# ESP32-P4 register map
Vendor: ESPRESSIF SYSTEMS (SHANGHAI) CO., LTD.; Series: ESP32 P-Series; File version: 3
CPU: RV32IMAFC r0p0, little endian, no MPU, FPU, 0 interrupt priority bits
Address unit: 32 bits
Registers are 32-bit, read-write, reset 0x0 unless marked. A register's access mark holds for its fields unless they carry their own. Offsets are from the block's base; [hi:lo] are bit positions; {n}, {i} and the like mark numbered series.

## CACHE (part 2 of 3) — CACHE Peripheral
Base 0x3FF10000
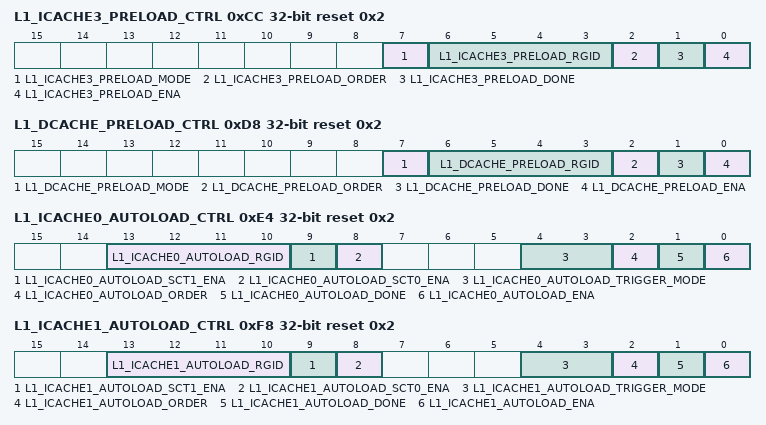
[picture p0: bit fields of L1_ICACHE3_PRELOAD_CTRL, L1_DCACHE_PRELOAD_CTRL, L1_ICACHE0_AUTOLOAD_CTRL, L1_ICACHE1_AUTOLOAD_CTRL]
0xCC L1_ICACHE3_PRELOAD_CTRL ro reset 0x2 — L1 instruction Cache 3 preload-operation control register
  [7] L1_ICACHE3_PRELOAD_MODE — The bit is used to configure the mode of l1 icache3 preload, 0: load data from next level memory, 1: not load data from next level memory.
  [6:3] L1_ICACHE3_PRELOAD_RGID — The bit is used to set the gid of l1 icache3 preload.
  [2] L1_ICACHE3_PRELOAD_ORDER — The bit is used to configure the direction of preload operation. 0: ascending, 1: descending.
  [1] L1_ICACHE3_PRELOAD_DONE — The bit is used to indicate whether preload operation is finished or not. 0: not finished. 1: finished.
  [0] L1_ICACHE3_PRELOAD_ENA — The bit is used to enable preload operation on L1-ICache3. It will be cleared by hardware automatically after preload operation is done.
0xD0 L1_ICACHE3_PRELOAD_ADDR ro — L1 instruction Cache 3 preload address configure register
  [31:0] L1_ICACHE3_PRELOAD_ADDR — Those bits are used to configure the start virtual address of preload on L1-ICache3, which should be used together with L1_ICACHE3_PRELOAD_SIZE_REG
0xD4 L1_ICACHE3_PRELOAD_SIZE ro — L1 instruction Cache 3 preload size configure register
  [13:0] L1_ICACHE3_PRELOAD_SIZE — Those bits are used to configure the size of the first section of prelock on L1-ICache3, which should be used together with L1_ICACHE3_PRELOAD_ADDR_REG
0xD8 L1_DCACHE_PRELOAD_CTRL access per field reset 0x2 — L1 data Cache preload-operation control register
  [7] L1_DCACHE_PRELOAD_MODE rw — The bit is used to configure the mode of l1 dcache preload, 0: load data from next level memory, 1: not load data from next level memory.
  [6:3] L1_DCACHE_PRELOAD_RGID rw — The bit is used to set the gid of l1 dcache preload.
  [2] L1_DCACHE_PRELOAD_ORDER rw — The bit is used to configure the direction of preload operation. 0: ascending, 1: descending.
  [1] L1_DCACHE_PRELOAD_DONE ro — The bit is used to indicate whether preload operation is finished or not. 0: not finished. 1: finished.
  [0] L1_DCACHE_PRELOAD_ENA rw — The bit is used to enable preload operation on L1-DCache. It will be cleared by hardware automatically after preload operation is done.
0xDC L1_DCACHE_PRELOAD_ADDR — L1 data Cache preload address configure register
  [31:0] L1_DCACHE_PRELOAD_ADDR — Those bits are used to configure the start virtual address of preload on L1-DCache, which should be used together with L1_DCACHE_PRELOAD_SIZE_REG
0xE0 L1_DCACHE_PRELOAD_SIZE — L1 data Cache preload size configure register
  [13:0] L1_DCACHE_PRELOAD_SIZE — Those bits are used to configure the size of the first section of prelock on L1-DCache, which should be used together with L1_DCACHE_PRELOAD_ADDR_REG
0xE4 L1_ICACHE0_AUTOLOAD_CTRL access per field reset 0x2 — L1 instruction Cache 0 autoload-operation control register
  [13:10] L1_ICACHE0_AUTOLOAD_RGID rw — The bit is used to set the gid of l1 icache0 autoload.
  [9] L1_ICACHE0_AUTOLOAD_SCT1_ENA rw — The bit is used to enable the second section for autoload operation on L1-ICache0.
  [8] L1_ICACHE0_AUTOLOAD_SCT0_ENA rw — The bit is used to enable the first section for autoload operation on L1-ICache0.
  [4:3] L1_ICACHE0_AUTOLOAD_TRIGGER_MODE rw — The field is used to configure trigger mode of autoload operation on L1-ICache0. 0/3: miss-trigger, 1: hit-trigger, 2: miss-hit-trigger.
  [2] L1_ICACHE0_AUTOLOAD_ORDER rw — The bit is used to configure the direction of autoload operation on L1-ICache0. 0: ascending. 1: descending.
  [1] L1_ICACHE0_AUTOLOAD_DONE ro — The bit is used to indicate whether autoload operation on L1-ICache0 is finished or not. 0: not finished. 1: finished.
  [0] L1_ICACHE0_AUTOLOAD_ENA rw — The bit is used to enable and disable autoload operation on L1-ICache0. 1: enable, 0: disable.
0xE8 L1_ICACHE0_AUTOLOAD_SCT0_ADDR — L1 instruction Cache 0 autoload section 0 address configure register
  [31:0] L1_ICACHE0_AUTOLOAD_SCT0_ADDR — Those bits are used to configure the start virtual address of the first section for autoload operation on L1-ICache0. Note that it should be used together with L1_ICACHE0_AUTOLOAD_SCT0_SIZE and L1_ICACHE_AUTOLOAD_SCT0_ENA.
0xEC L1_ICACHE0_AUTOLOAD_SCT0_SIZE — L1 instruction Cache 0 autoload section 0 size configure register
  [27:0] L1_ICACHE0_AUTOLOAD_SCT0_SIZE — Those bits are used to configure the size of the first section for autoload operation on L1-ICache0. Note that it should be used together with L1_ICACHE0_AUTOLOAD_SCT0_ADDR and L1_ICACHE_AUTOLOAD_SCT0_ENA.
0xF0 L1_ICACHE0_AUTOLOAD_SCT1_ADDR — L1 instruction Cache 0 autoload section 1 address configure register
  [31:0] L1_ICACHE0_AUTOLOAD_SCT1_ADDR — Those bits are used to configure the start virtual address of the second section for autoload operation on L1-ICache0. Note that it should be used together with L1_ICACHE0_AUTOLOAD_SCT1_SIZE and L1_ICACHE_AUTOLOAD_SCT1_ENA.
0xF4 L1_ICACHE0_AUTOLOAD_SCT1_SIZE — L1 instruction Cache 0 autoload section 1 size configure register
  [27:0] L1_ICACHE0_AUTOLOAD_SCT1_SIZE — Those bits are used to configure the size of the second section for autoload operation on L1-ICache0. Note that it should be used together with L1_ICACHE0_AUTOLOAD_SCT1_ADDR and L1_ICACHE_AUTOLOAD_SCT1_ENA.
0xF8 L1_ICACHE1_AUTOLOAD_CTRL access per field reset 0x2 — L1 instruction Cache 1 autoload-operation control register
  [13:10] L1_ICACHE1_AUTOLOAD_RGID rw — The bit is used to set the gid of l1 icache1 autoload.
  [9] L1_ICACHE1_AUTOLOAD_SCT1_ENA rw — The bit is used to enable the second section for autoload operation on L1-ICache1.
  [8] L1_ICACHE1_AUTOLOAD_SCT0_ENA rw — The bit is used to enable the first section for autoload operation on L1-ICache1.
  [4:3] L1_ICACHE1_AUTOLOAD_TRIGGER_MODE rw — The field is used to configure trigger mode of autoload operation on L1-ICache1. 0/3: miss-trigger, 1: hit-trigger, 2: miss-hit-trigger.
  [2] L1_ICACHE1_AUTOLOAD_ORDER rw — The bit is used to configure the direction of autoload operation on L1-ICache1. 0: ascending. 1: descending.
  [1] L1_ICACHE1_AUTOLOAD_DONE ro — The bit is used to indicate whether autoload operation on L1-ICache1 is finished or not. 0: not finished. 1: finished.
  [0] L1_ICACHE1_AUTOLOAD_ENA rw — The bit is used to enable and disable autoload operation on L1-ICache1. 1: enable, 0: disable.
0xFC L1_ICACHE1_AUTOLOAD_SCT0_ADDR — L1 instruction Cache 1 autoload section 0 address configure register
  [31:0] L1_ICACHE1_AUTOLOAD_SCT0_ADDR — Those bits are used to configure the start virtual address of the first section for autoload operation on L1-ICache1. Note that it should be used together with L1_ICACHE1_AUTOLOAD_SCT0_SIZE and L1_ICACHE_AUTOLOAD_SCT0_ENA.
0x100 L1_ICACHE1_AUTOLOAD_SCT0_SIZE — L1 instruction Cache 1 autoload section 0 size configure register
  [27:0] L1_ICACHE1_AUTOLOAD_SCT0_SIZE — Those bits are used to configure the size of the first section for autoload operation on L1-ICache1. Note that it should be used together with L1_ICACHE1_AUTOLOAD_SCT0_ADDR and L1_ICACHE_AUTOLOAD_SCT0_ENA.
0x104 L1_ICACHE1_AUTOLOAD_SCT1_ADDR — L1 instruction Cache 1 autoload section 1 address configure register
  [31:0] L1_ICACHE1_AUTOLOAD_SCT1_ADDR — Those bits are used to configure the start virtual address of the second section for autoload operation on L1-ICache1. Note that it should be used together with L1_ICACHE1_AUTOLOAD_SCT1_SIZE and L1_ICACHE_AUTOLOAD_SCT1_ENA.
0x108 L1_ICACHE1_AUTOLOAD_SCT1_SIZE — L1 instruction Cache 1 autoload section 1 size configure register
  [27:0] L1_ICACHE1_AUTOLOAD_SCT1_SIZE — Those bits are used to configure the size of the second section for autoload operation on L1-ICache1. Note that it should be used together with L1_ICACHE1_AUTOLOAD_SCT1_ADDR and L1_ICACHE_AUTOLOAD_SCT1_ENA.
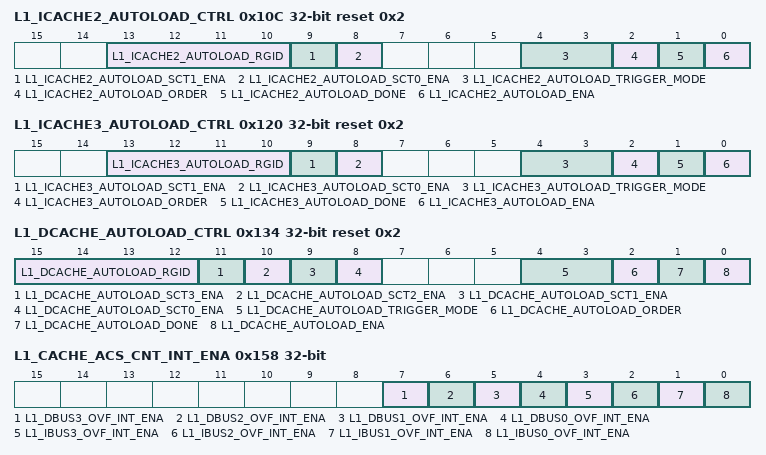
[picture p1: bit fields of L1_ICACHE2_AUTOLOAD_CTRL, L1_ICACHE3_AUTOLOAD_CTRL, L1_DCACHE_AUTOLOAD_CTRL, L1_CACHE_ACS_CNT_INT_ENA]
0x10C L1_ICACHE2_AUTOLOAD_CTRL ro reset 0x2 — L1 instruction Cache 2 autoload-operation control register
  [13:10] L1_ICACHE2_AUTOLOAD_RGID — The bit is used to set the gid of l1 icache2 autoload.
  [9] L1_ICACHE2_AUTOLOAD_SCT1_ENA — The bit is used to enable the second section for autoload operation on L1-ICache2.
  [8] L1_ICACHE2_AUTOLOAD_SCT0_ENA — The bit is used to enable the first section for autoload operation on L1-ICache2.
  [4:3] L1_ICACHE2_AUTOLOAD_TRIGGER_MODE — The field is used to configure trigger mode of autoload operation on L1-ICache2. 0/3: miss-trigger, 1: hit-trigger, 2: miss-hit-trigger.
  [2] L1_ICACHE2_AUTOLOAD_ORDER — The bit is used to configure the direction of autoload operation on L1-ICache2. 0: ascending. 1: descending.
  [1] L1_ICACHE2_AUTOLOAD_DONE — The bit is used to indicate whether autoload operation on L1-ICache2 is finished or not. 0: not finished. 1: finished.
  [0] L1_ICACHE2_AUTOLOAD_ENA — The bit is used to enable and disable autoload operation on L1-ICache2. 1: enable, 0: disable.
0x110 L1_ICACHE2_AUTOLOAD_SCT0_ADDR ro — L1 instruction Cache 2 autoload section 0 address configure register
  [31:0] L1_ICACHE2_AUTOLOAD_SCT0_ADDR — Those bits are used to configure the start virtual address of the first section for autoload operation on L1-ICache2. Note that it should be used together with L1_ICACHE2_AUTOLOAD_SCT0_SIZE and L1_ICACHE_AUTOLOAD_SCT0_ENA.
0x114 L1_ICACHE2_AUTOLOAD_SCT0_SIZE ro — L1 instruction Cache 2 autoload section 0 size configure register
  [27:0] L1_ICACHE2_AUTOLOAD_SCT0_SIZE — Those bits are used to configure the size of the first section for autoload operation on L1-ICache2. Note that it should be used together with L1_ICACHE2_AUTOLOAD_SCT0_ADDR and L1_ICACHE_AUTOLOAD_SCT0_ENA.
0x118 L1_ICACHE2_AUTOLOAD_SCT1_ADDR ro — L1 instruction Cache 2 autoload section 1 address configure register
  [31:0] L1_ICACHE2_AUTOLOAD_SCT1_ADDR — Those bits are used to configure the start virtual address of the second section for autoload operation on L1-ICache2. Note that it should be used together with L1_ICACHE2_AUTOLOAD_SCT1_SIZE and L1_ICACHE_AUTOLOAD_SCT1_ENA.
0x11C L1_ICACHE2_AUTOLOAD_SCT1_SIZE ro — L1 instruction Cache 2 autoload section 1 size configure register
  [27:0] L1_ICACHE2_AUTOLOAD_SCT1_SIZE — Those bits are used to configure the size of the second section for autoload operation on L1-ICache2. Note that it should be used together with L1_ICACHE2_AUTOLOAD_SCT1_ADDR and L1_ICACHE_AUTOLOAD_SCT1_ENA.
0x120 L1_ICACHE3_AUTOLOAD_CTRL ro reset 0x2 — L1 instruction Cache 3 autoload-operation control register
  [13:10] L1_ICACHE3_AUTOLOAD_RGID — The bit is used to set the gid of l1 icache3 autoload.
  [9] L1_ICACHE3_AUTOLOAD_SCT1_ENA — The bit is used to enable the second section for autoload operation on L1-ICache3.
  [8] L1_ICACHE3_AUTOLOAD_SCT0_ENA — The bit is used to enable the first section for autoload operation on L1-ICache3.
  [4:3] L1_ICACHE3_AUTOLOAD_TRIGGER_MODE — The field is used to configure trigger mode of autoload operation on L1-ICache3. 0/3: miss-trigger, 1: hit-trigger, 2: miss-hit-trigger.
  [2] L1_ICACHE3_AUTOLOAD_ORDER — The bit is used to configure the direction of autoload operation on L1-ICache3. 0: ascending. 1: descending.
  [1] L1_ICACHE3_AUTOLOAD_DONE — The bit is used to indicate whether autoload operation on L1-ICache3 is finished or not. 0: not finished. 1: finished.
  [0] L1_ICACHE3_AUTOLOAD_ENA — The bit is used to enable and disable autoload operation on L1-ICache3. 1: enable, 0: disable.
0x124 L1_ICACHE3_AUTOLOAD_SCT0_ADDR ro — L1 instruction Cache 3 autoload section 0 address configure register
  [31:0] L1_ICACHE3_AUTOLOAD_SCT0_ADDR — Those bits are used to configure the start virtual address of the first section for autoload operation on L1-ICache3. Note that it should be used together with L1_ICACHE3_AUTOLOAD_SCT0_SIZE and L1_ICACHE_AUTOLOAD_SCT0_ENA.
0x128 L1_ICACHE3_AUTOLOAD_SCT0_SIZE ro — L1 instruction Cache 3 autoload section 0 size configure register
  [27:0] L1_ICACHE3_AUTOLOAD_SCT0_SIZE — Those bits are used to configure the size of the first section for autoload operation on L1-ICache3. Note that it should be used together with L1_ICACHE3_AUTOLOAD_SCT0_ADDR and L1_ICACHE_AUTOLOAD_SCT0_ENA.
0x12C L1_ICACHE3_AUTOLOAD_SCT1_ADDR ro — L1 instruction Cache 3 autoload section 1 address configure register
  [31:0] L1_ICACHE3_AUTOLOAD_SCT1_ADDR — Those bits are used to configure the start virtual address of the second section for autoload operation on L1-ICache3. Note that it should be used together with L1_ICACHE3_AUTOLOAD_SCT1_SIZE and L1_ICACHE_AUTOLOAD_SCT1_ENA.
0x130 L1_ICACHE3_AUTOLOAD_SCT1_SIZE ro — L1 instruction Cache 3 autoload section 1 size configure register
  [27:0] L1_ICACHE3_AUTOLOAD_SCT1_SIZE — Reserved
0x134 L1_DCACHE_AUTOLOAD_CTRL access per field reset 0x2 — L1 data Cache autoload-operation control register
  [15:12] L1_DCACHE_AUTOLOAD_RGID rw — The bit is used to set the gid of l1 dcache autoload.
  [11] L1_DCACHE_AUTOLOAD_SCT3_ENA rw — The bit is used to enable the fourth section for autoload operation on L1-DCache.
  [10] L1_DCACHE_AUTOLOAD_SCT2_ENA rw — The bit is used to enable the third section for autoload operation on L1-DCache.
  [9] L1_DCACHE_AUTOLOAD_SCT1_ENA rw — The bit is used to enable the second section for autoload operation on L1-DCache.
  [8] L1_DCACHE_AUTOLOAD_SCT0_ENA rw — The bit is used to enable the first section for autoload operation on L1-DCache.
  [4:3] L1_DCACHE_AUTOLOAD_TRIGGER_MODE rw — The field is used to configure trigger mode of autoload operation on L1-DCache. 0/3: miss-trigger, 1: hit-trigger, 2: miss-hit-trigger.
  [2] L1_DCACHE_AUTOLOAD_ORDER rw — The bit is used to configure the direction of autoload operation on L1-DCache. 0: ascending. 1: descending.
  [1] L1_DCACHE_AUTOLOAD_DONE ro — The bit is used to indicate whether autoload operation on L1-DCache is finished or not. 0: not finished. 1: finished.
  [0] L1_DCACHE_AUTOLOAD_ENA rw — The bit is used to enable and disable autoload operation on L1-DCache. 1: enable, 0: disable.
0x138 L1_DCACHE_AUTOLOAD_SCT0_ADDR — L1 data Cache autoload section 0 address configure register
  [31:0] L1_DCACHE_AUTOLOAD_SCT0_ADDR — Those bits are used to configure the start virtual address of the first section for autoload operation on L1-DCache. Note that it should be used together with L1_DCACHE_AUTOLOAD_SCT0_SIZE and L1_DCACHE_AUTOLOAD_SCT0_ENA.
0x13C L1_DCACHE_AUTOLOAD_SCT0_SIZE — L1 data Cache autoload section 0 size configure register
  [27:0] L1_DCACHE_AUTOLOAD_SCT0_SIZE — Those bits are used to configure the size of the first section for autoload operation on L1-DCache. Note that it should be used together with L1_DCACHE_AUTOLOAD_SCT0_ADDR and L1_DCACHE_AUTOLOAD_SCT0_ENA.
0x140 L1_DCACHE_AUTOLOAD_SCT1_ADDR — L1 data Cache autoload section 1 address configure register
  [31:0] L1_DCACHE_AUTOLOAD_SCT1_ADDR — Those bits are used to configure the start virtual address of the second section for autoload operation on L1-DCache. Note that it should be used together with L1_DCACHE_AUTOLOAD_SCT1_SIZE and L1_DCACHE_AUTOLOAD_SCT1_ENA.
0x144 L1_DCACHE_AUTOLOAD_SCT1_SIZE — L1 data Cache autoload section 1 size configure register
  [27:0] L1_DCACHE_AUTOLOAD_SCT1_SIZE — Those bits are used to configure the size of the second section for autoload operation on L1-DCache. Note that it should be used together with L1_DCACHE_AUTOLOAD_SCT1_ADDR and L1_DCACHE_AUTOLOAD_SCT1_ENA.
0x148 L1_DCACHE_AUTOLOAD_SCT2_ADDR — L1 data Cache autoload section 2 address configure register
  [31:0] L1_DCACHE_AUTOLOAD_SCT2_ADDR — Those bits are used to configure the start virtual address of the third section for autoload operation on L1-DCache. Note that it should be used together with L1_DCACHE_AUTOLOAD_SCT2_SIZE and L1_DCACHE_AUTOLOAD_SCT2_ENA.
0x14C L1_DCACHE_AUTOLOAD_SCT2_SIZE — L1 data Cache autoload section 2 size configure register
  [27:0] L1_DCACHE_AUTOLOAD_SCT2_SIZE — Those bits are used to configure the size of the third section for autoload operation on L1-DCache. Note that it should be used together with L1_DCACHE_AUTOLOAD_SCT2_ADDR and L1_DCACHE_AUTOLOAD_SCT2_ENA.
0x150 L1_DCACHE_AUTOLOAD_SCT3_ADDR — L1 data Cache autoload section 1 address configure register
  [31:0] L1_DCACHE_AUTOLOAD_SCT3_ADDR — Those bits are used to configure the start virtual address of the fourth section for autoload operation on L1-DCache. Note that it should be used together with L1_DCACHE_AUTOLOAD_SCT3_SIZE and L1_DCACHE_AUTOLOAD_SCT3_ENA.
0x154 L1_DCACHE_AUTOLOAD_SCT3_SIZE — L1 data Cache autoload section 1 size configure register
  [27:0] L1_DCACHE_AUTOLOAD_SCT3_SIZE — Those bits are used to configure the size of the fourth section for autoload operation on L1-DCache. Note that it should be used together with L1_DCACHE_AUTOLOAD_SCT3_ADDR and L1_DCACHE_AUTOLOAD_SCT3_ENA.
0x158 L1_CACHE_ACS_CNT_INT_ENA access per field — Cache Access Counter Interrupt enable register
  [7] L1_DBUS3_OVF_INT_ENA ro — Reserved
  [6] L1_DBUS2_OVF_INT_ENA ro — Reserved
  [5] L1_DBUS1_OVF_INT_ENA rw — The bit is used to enable interrupt of one of counters overflow that occurs in L1-DCache due to bus1 accesses L1-DCache.
  [4] L1_DBUS0_OVF_INT_ENA rw — The bit is used to enable interrupt of one of counters overflow that occurs in L1-DCache due to bus0 accesses L1-DCache.
  [3] L1_IBUS3_OVF_INT_ENA ro — Reserved
  [2] L1_IBUS2_OVF_INT_ENA ro — Reserved
  [1] L1_IBUS1_OVF_INT_ENA rw — The bit is used to enable interrupt of one of counters overflow that occurs in L1-ICache1 due to bus1 accesses L1-ICache1.
  [0] L1_IBUS0_OVF_INT_ENA rw — The bit is used to enable interrupt of one of counters overflow that occurs in L1-ICache0 due to bus0 accesses L1-ICache0.
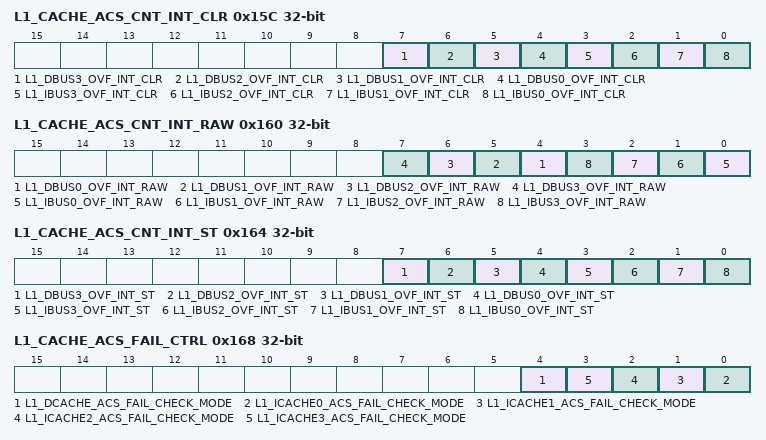
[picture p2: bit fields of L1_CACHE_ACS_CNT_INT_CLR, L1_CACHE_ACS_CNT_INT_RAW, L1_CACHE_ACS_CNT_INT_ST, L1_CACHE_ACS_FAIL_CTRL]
0x15C L1_CACHE_ACS_CNT_INT_CLR access per field — Cache Access Counter Interrupt clear register
  [7] L1_DBUS3_OVF_INT_CLR ro — Reserved
  [6] L1_DBUS2_OVF_INT_CLR ro — Reserved
  [5] L1_DBUS1_OVF_INT_CLR wo — The bit is used to clear counters overflow interrupt and counters in L1-DCache due to bus1 accesses L1-DCache.
  [4] L1_DBUS0_OVF_INT_CLR wo — The bit is used to clear counters overflow interrupt and counters in L1-DCache due to bus0 accesses L1-DCache.
  [3] L1_IBUS3_OVF_INT_CLR ro — Reserved
  [2] L1_IBUS2_OVF_INT_CLR ro — Reserved
  [1] L1_IBUS1_OVF_INT_CLR wo — The bit is used to clear counters overflow interrupt and counters in L1-ICache1 due to bus1 accesses L1-ICache1.
  [0] L1_IBUS0_OVF_INT_CLR wo — The bit is used to clear counters overflow interrupt and counters in L1-ICache0 due to bus0 accesses L1-ICache0.
0x160 L1_CACHE_ACS_CNT_INT_RAW — Cache Access Counter Interrupt raw register
  [n+4] L1_DBUS{n}_OVF_INT_RAW (n=0..3) — The raw bit of the interrupt of one of counters overflow that occurs in L1-DCache due to bus{n} accesses L1-DCache.
  [n] L1_IBUS{n}_OVF_INT_RAW (n=0..3) — The raw bit of the interrupt of one of counters overflow that occurs in L1-ICache{n} due to bus{n} accesses L1-ICache{n}.
0x164 L1_CACHE_ACS_CNT_INT_ST ro — Cache Access Counter Interrupt status register
  [7] L1_DBUS3_OVF_INT_ST — Reserved
  [6] L1_DBUS2_OVF_INT_ST — Reserved
  [5] L1_DBUS1_OVF_INT_ST — The bit indicates the interrupt status of one of counters overflow that occurs in L1-DCache due to bus1 accesses L1-DCache.
  [4] L1_DBUS0_OVF_INT_ST — The bit indicates the interrupt status of one of counters overflow that occurs in L1-DCache due to bus0 accesses L1-DCache.
  [3] L1_IBUS3_OVF_INT_ST — Reserved
  [2] L1_IBUS2_OVF_INT_ST — Reserved
  [1] L1_IBUS1_OVF_INT_ST — The bit indicates the interrupt status of one of counters overflow that occurs in L1-ICache1 due to bus1 accesses L1-ICache1.
  [0] L1_IBUS0_OVF_INT_ST — The bit indicates the interrupt status of one of counters overflow that occurs in L1-ICache0 due to bus0 accesses L1-ICache0.
0x168 L1_CACHE_ACS_FAIL_CTRL — Cache Access Fail Configuration register
  [4] L1_DCACHE_ACS_FAIL_CHECK_MODE — The bit is used to configure l1 dcache access fail check mode. 0: the access fail is not propagated to the request, 1: the access fail is propagated to the request
  [n] L1_ICACHE{n}_ACS_FAIL_CHECK_MODE (n=0..3) — The bit is used to configure l1 icache{n} access fail check mode. 0: the access fail is not propagated to the request, 1: the access fail is propagated to the request
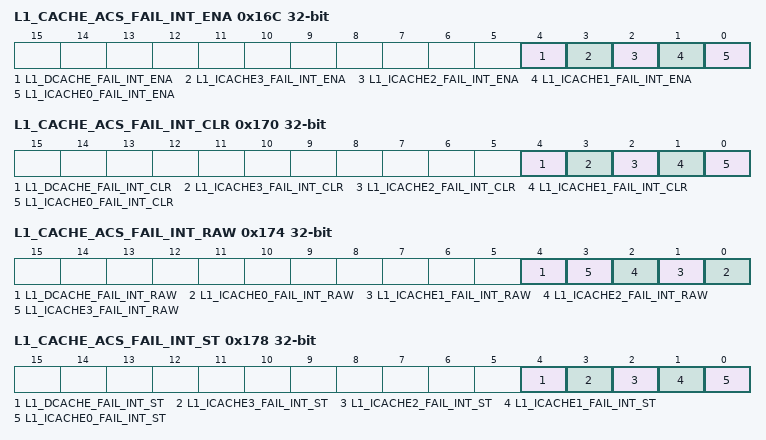
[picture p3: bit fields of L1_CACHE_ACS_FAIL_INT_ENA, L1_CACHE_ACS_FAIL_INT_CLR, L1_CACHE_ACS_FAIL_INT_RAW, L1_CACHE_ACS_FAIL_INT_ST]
0x16C L1_CACHE_ACS_FAIL_INT_ENA access per field — Cache Access Fail Interrupt enable register
  [4] L1_DCACHE_FAIL_INT_ENA rw — The bit is used to enable interrupt of access fail that occurs in L1-DCache due to cpu accesses L1-DCache.
  [3] L1_ICACHE3_FAIL_INT_ENA ro — Reserved
  [2] L1_ICACHE2_FAIL_INT_ENA ro — Reserved
  [1] L1_ICACHE1_FAIL_INT_ENA rw — The bit is used to enable interrupt of access fail that occurs in L1-ICache1 due to cpu accesses L1-ICache1.
  [0] L1_ICACHE0_FAIL_INT_ENA rw — The bit is used to enable interrupt of access fail that occurs in L1-ICache0 due to cpu accesses L1-ICache0.
0x170 L1_CACHE_ACS_FAIL_INT_CLR access per field — L1-Cache Access Fail Interrupt clear register
  [4] L1_DCACHE_FAIL_INT_CLR wo — The bit is used to clear interrupt of access fail that occurs in L1-DCache due to cpu accesses L1-DCache.
  [3] L1_ICACHE3_FAIL_INT_CLR ro — Reserved
  [2] L1_ICACHE2_FAIL_INT_CLR ro — Reserved
  [1] L1_ICACHE1_FAIL_INT_CLR wo — The bit is used to clear interrupt of access fail that occurs in L1-ICache1 due to cpu accesses L1-ICache1.
  [0] L1_ICACHE0_FAIL_INT_CLR wo — The bit is used to clear interrupt of access fail that occurs in L1-ICache0 due to cpu accesses L1-ICache0.
0x174 L1_CACHE_ACS_FAIL_INT_RAW — Cache Access Fail Interrupt raw register
  [4] L1_DCACHE_FAIL_INT_RAW — The raw bit of the interrupt of access fail that occurs in L1-DCache.
  [n] L1_ICACHE{n}_FAIL_INT_RAW (n=0..3) — The raw bit of the interrupt of access fail that occurs in L1-ICache{n}.
0x178 L1_CACHE_ACS_FAIL_INT_ST ro — Cache Access Fail Interrupt status register
  [4] L1_DCACHE_FAIL_INT_ST — The bit indicates the interrupt status of access fail that occurs in L1-DCache due to cpu accesses L1-DCache.
  [3] L1_ICACHE3_FAIL_INT_ST — Reserved
  [2] L1_ICACHE2_FAIL_INT_ST — Reserved
  [1] L1_ICACHE1_FAIL_INT_ST — The bit indicates the interrupt status of access fail that occurs in L1-ICache1 due to cpu accesses L1-ICache.
  [0] L1_ICACHE0_FAIL_INT_ST — The bit indicates the interrupt status of access fail that occurs in L1-ICache0 due to cpu accesses L1-ICache.
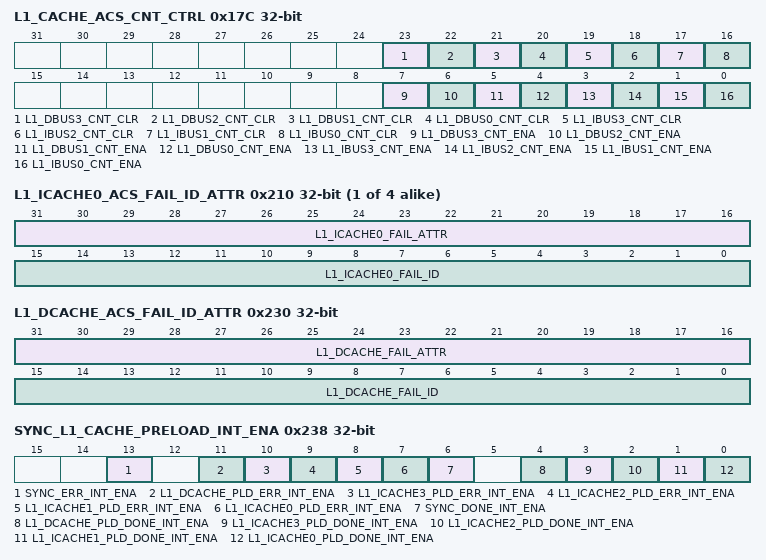
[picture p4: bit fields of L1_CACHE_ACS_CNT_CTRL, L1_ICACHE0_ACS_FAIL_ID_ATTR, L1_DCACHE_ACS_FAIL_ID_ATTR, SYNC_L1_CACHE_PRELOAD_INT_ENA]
0x17C L1_CACHE_ACS_CNT_CTRL access per field — Cache Access Counter enable and clear register
  [23] L1_DBUS3_CNT_CLR ro — Reserved
  [22] L1_DBUS2_CNT_CLR ro — Reserved
  [21] L1_DBUS1_CNT_CLR wo — The bit is used to clear dbus1 counter in L1-DCache.
  [20] L1_DBUS0_CNT_CLR wo — The bit is used to clear dbus0 counter in L1-DCache.
  [19] L1_IBUS3_CNT_CLR ro — Reserved
  [18] L1_IBUS2_CNT_CLR ro — Reserved
  [17] L1_IBUS1_CNT_CLR wo — The bit is used to clear ibus1 counter in L1-ICache1.
  [16] L1_IBUS0_CNT_CLR wo — The bit is used to clear ibus0 counter in L1-ICache0.
  [7] L1_DBUS3_CNT_ENA ro — Reserved
  [6] L1_DBUS2_CNT_ENA ro — Reserved
  [5] L1_DBUS1_CNT_ENA rw — The bit is used to enable dbus1 counter in L1-DCache.
  [4] L1_DBUS0_CNT_ENA rw — The bit is used to enable dbus0 counter in L1-DCache.
  [3] L1_IBUS3_CNT_ENA ro — Reserved
  [2] L1_IBUS2_CNT_ENA ro — Reserved
  [1] L1_IBUS1_CNT_ENA rw — The bit is used to enable ibus1 counter in L1-ICache1.
  [0] L1_IBUS0_CNT_ENA rw — The bit is used to enable ibus0 counter in L1-ICache0.
{0x180+0x10*i} L1_IBUS{i}_ACS_HIT_CNT ro (i=0..3) — L1-ICache bus{i} Hit-Access Counter register
  [31:0] L1_IBUS{i}_HIT_CNT — The register records the number of hits when bus{i} accesses L1-ICache{i}.
{0x184+0x10*i} L1_IBUS{i}_ACS_MISS_CNT ro (i=0..3) — L1-ICache bus{i} Miss-Access Counter register
  [31:0] L1_IBUS{i}_MISS_CNT — The register records the number of missing when bus{i} accesses L1-ICache{i}.
{0x188+0x10*i} L1_IBUS{i}_ACS_CONFLICT_CNT ro (i=0..3) — L1-ICache bus{i} Conflict-Access Counter register
  [31:0] L1_IBUS{i}_CONFLICT_CNT — The register records the number of access-conflicts when bus{i} accesses L1-ICache{i}.
{0x18C+0x10*i} L1_IBUS{i}_ACS_NXTLVL_RD_CNT ro (i=0..3) — L1-ICache bus{i} Next-Level-Access Counter register
  [31:0] L1_IBUS{i}_NXTLVL_RD_CNT — The register records the number of times that L1-ICache accesses L2-Cache due to bus{i} accessing L1-ICache{i}.
{0x1C0+0x14*i} L1_DBUS{i}_ACS_HIT_CNT ro (i=0..3) — L1-DCache bus{i} Hit-Access Counter register
  [31:0] L1_DBUS{i}_HIT_CNT — The register records the number of hits when bus{i} accesses L1-DCache.
{0x1C4+0x14*i} L1_DBUS{i}_ACS_MISS_CNT ro (i=0..3) — L1-DCache bus{i} Miss-Access Counter register
  [31:0] L1_DBUS{i}_MISS_CNT — The register records the number of missing when bus{i} accesses L1-DCache.
{0x1C8+0x14*i} L1_DBUS{i}_ACS_CONFLICT_CNT ro (i=0..3) — L1-DCache bus{i} Conflict-Access Counter register
  [31:0] L1_DBUS{i}_CONFLICT_CNT — The register records the number of access-conflicts when bus{i} accesses L1-DCache.
{0x1CC+0x14*i} L1_DBUS{i}_ACS_NXTLVL_RD_CNT ro (i=0..3) — L1-DCache bus{i} Next-Level-Access Counter register
  [31:0] L1_DBUS{i}_NXTLVL_RD_CNT — The register records the number of times that L1-DCache accesses L2-Cache due to bus{i} accessing L1-DCache.
{0x1D0+0x14*i} L1_DBUS{i}_ACS_NXTLVL_WR_CNT ro (i=0..2) — L1-DCache bus{i} WB-Access Counter register
  [31:0] L1_DBUS{i}_NXTLVL_WR_CNT — The register records the number of write back when bus{i} accesses L1-DCache.
0x20C L1_DBUS3_ACS_NXTLVL_WR_CNT ro — L1-DCache bus3 WB-Access Counter register
  [31:0] L1_DBUS3_NXTLVL_WR_CNT — The register records the number of write back when bus0 accesses L1-DCache.
{0x210+8i} L1_ICACHE{i}_ACS_FAIL_ID_ATTR ro (i=0..3) — L1-ICache0 Access Fail ID/attribution information register
  [31:16] L1_ICACHE{i}_FAIL_ATTR — The register records the attribution of fail-access when cache{i} accesses L1-ICache.
  [15:0] L1_ICACHE{i}_FAIL_ID — The register records the ID of fail-access when cache{i} accesses L1-ICache.
{0x214+8i} L1_ICACHE{i}_ACS_FAIL_ADDR ro (i=0..3) — L1-ICache0 Access Fail Address information register
  [31:0] L1_ICACHE{i}_FAIL_ADDR — The register records the address of fail-access when cache{i} accesses L1-ICache.
0x230 L1_DCACHE_ACS_FAIL_ID_ATTR ro — L1-DCache Access Fail ID/attribution information register
  [31:16] L1_DCACHE_FAIL_ATTR — The register records the attribution of fail-access when cache accesses L1-DCache.
  [15:0] L1_DCACHE_FAIL_ID — The register records the ID of fail-access when cache accesses L1-DCache.
0x234 L1_DCACHE_ACS_FAIL_ADDR ro — L1-DCache Access Fail Address information register
  [31:0] L1_DCACHE_FAIL_ADDR — The register records the address of fail-access when cache accesses L1-DCache.
0x238 SYNC_L1_CACHE_PRELOAD_INT_ENA access per field — L1-Cache Access Fail Interrupt enable register
  [13] SYNC_ERR_INT_ENA rw — The bit is used to enable interrupt of Cache sync-operation error.
  [11] L1_DCACHE_PLD_ERR_INT_ENA rw — The bit is used to enable interrupt of L1-DCache preload-operation error.
  [10] L1_ICACHE3_PLD_ERR_INT_ENA ro — Reserved
  [9] L1_ICACHE2_PLD_ERR_INT_ENA ro — Reserved
  [8] L1_ICACHE1_PLD_ERR_INT_ENA rw — The bit is used to enable interrupt of L1-ICache1 preload-operation error.
  [7] L1_ICACHE0_PLD_ERR_INT_ENA rw — The bit is used to enable interrupt of L1-ICache0 preload-operation error.
  [6] SYNC_DONE_INT_ENA rw — The bit is used to enable interrupt of Cache sync-operation done.
  [4] L1_DCACHE_PLD_DONE_INT_ENA rw — The bit is used to enable interrupt of L1-DCache preload-operation. If preload operation is done, interrupt occurs.
  [3] L1_ICACHE3_PLD_DONE_INT_ENA ro — Reserved
  [2] L1_ICACHE2_PLD_DONE_INT_ENA ro — Reserved
  [1] L1_ICACHE1_PLD_DONE_INT_ENA rw — The bit is used to enable interrupt of L1-ICache1 preload-operation. If preload operation is done, interrupt occurs.
  [0] L1_ICACHE0_PLD_DONE_INT_ENA rw — The bit is used to enable interrupt of L1-ICache0 preload-operation. If preload operation is done, interrupt occurs.
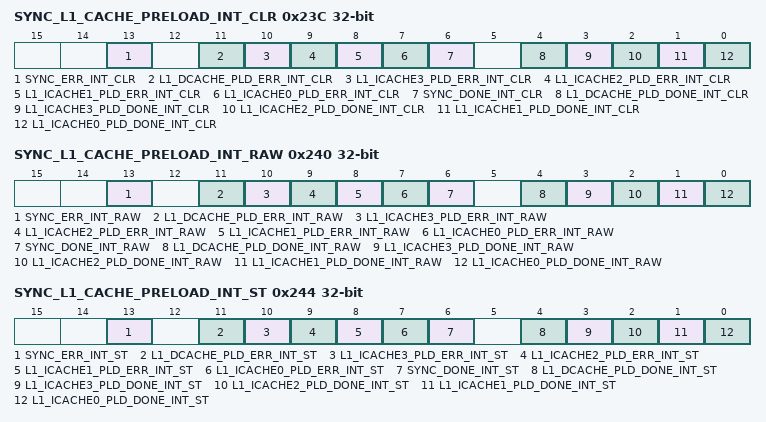
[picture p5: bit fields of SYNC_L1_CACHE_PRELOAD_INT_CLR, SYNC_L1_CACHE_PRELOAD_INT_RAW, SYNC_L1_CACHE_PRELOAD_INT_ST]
0x23C SYNC_L1_CACHE_PRELOAD_INT_CLR access per field — Sync Preload operation Interrupt clear register
  [13] SYNC_ERR_INT_CLR wo — The bit is used to clear interrupt of Cache sync-operation error.
  [11] L1_DCACHE_PLD_ERR_INT_CLR wo — The bit is used to clear interrupt of L1-DCache preload-operation error.
  [10] L1_ICACHE3_PLD_ERR_INT_CLR ro — Reserved
  [9] L1_ICACHE2_PLD_ERR_INT_CLR ro — Reserved
  [8] L1_ICACHE1_PLD_ERR_INT_CLR wo — The bit is used to clear interrupt of L1-ICache1 preload-operation error.
  [7] L1_ICACHE0_PLD_ERR_INT_CLR wo — The bit is used to clear interrupt of L1-ICache0 preload-operation error.
  [6] SYNC_DONE_INT_CLR wo — The bit is used to clear interrupt that occurs only when Cache sync-operation is done.
  [4] L1_DCACHE_PLD_DONE_INT_CLR wo — The bit is used to clear interrupt that occurs only when L1-DCache preload-operation is done.
  [3] L1_ICACHE3_PLD_DONE_INT_CLR ro — Reserved
  [2] L1_ICACHE2_PLD_DONE_INT_CLR ro — Reserved
  [1] L1_ICACHE1_PLD_DONE_INT_CLR wo — The bit is used to clear interrupt that occurs only when L1-ICache1 preload-operation is done.
  [0] L1_ICACHE0_PLD_DONE_INT_CLR wo — The bit is used to clear interrupt that occurs only when L1-ICache0 preload-operation is done.
0x240 SYNC_L1_CACHE_PRELOAD_INT_RAW — Sync Preload operation Interrupt raw register
  [13] SYNC_ERR_INT_RAW — The raw bit of the interrupt that occurs only when Cache sync-operation error occurs.
  [11] L1_DCACHE_PLD_ERR_INT_RAW — The raw bit of the interrupt that occurs only when L1-DCache preload-operation error occurs.
  [10] L1_ICACHE3_PLD_ERR_INT_RAW — Reserved
  [9] L1_ICACHE2_PLD_ERR_INT_RAW — Reserved
  [8] L1_ICACHE1_PLD_ERR_INT_RAW — The raw bit of the interrupt that occurs only when L1-ICache1 preload-operation error occurs.
  [7] L1_ICACHE0_PLD_ERR_INT_RAW — The raw bit of the interrupt that occurs only when L1-ICache0 preload-operation error occurs.
  [6] SYNC_DONE_INT_RAW — The raw bit of the interrupt that occurs only when Cache sync-operation is done.
  [4] L1_DCACHE_PLD_DONE_INT_RAW — The raw bit of the interrupt that occurs only when L1-DCache preload-operation is done.
  [3] L1_ICACHE3_PLD_DONE_INT_RAW — Reserved
  [2] L1_ICACHE2_PLD_DONE_INT_RAW — Reserved
  [1] L1_ICACHE1_PLD_DONE_INT_RAW — The raw bit of the interrupt that occurs only when L1-ICache1 preload-operation is done.
  [0] L1_ICACHE0_PLD_DONE_INT_RAW — The raw bit of the interrupt that occurs only when L1-ICache0 preload-operation is done.
0x244 SYNC_L1_CACHE_PRELOAD_INT_ST ro — L1-Cache Access Fail Interrupt status register
  [13] SYNC_ERR_INT_ST — The bit indicates the status of the interrupt of Cache sync-operation error.
  [11] L1_DCACHE_PLD_ERR_INT_ST — The bit indicates the status of the interrupt of L1-DCache preload-operation error.
  [10] L1_ICACHE3_PLD_ERR_INT_ST — Reserved
  [9] L1_ICACHE2_PLD_ERR_INT_ST — Reserved
  [8] L1_ICACHE1_PLD_ERR_INT_ST — The bit indicates the status of the interrupt of L1-ICache1 preload-operation error.
  [7] L1_ICACHE0_PLD_ERR_INT_ST — The bit indicates the status of the interrupt of L1-ICache0 preload-operation error.
  [6] SYNC_DONE_INT_ST — The bit indicates the status of the interrupt that occurs only when Cache sync-operation is done.
  [4] L1_DCACHE_PLD_DONE_INT_ST — The bit indicates the status of the interrupt that occurs only when L1-DCache preload-operation is done.
  [3] L1_ICACHE3_PLD_DONE_INT_ST — Reserved
  [2] L1_ICACHE2_PLD_DONE_INT_ST — Reserved
  [1] L1_ICACHE1_PLD_DONE_INT_ST — The bit indicates the status of the interrupt that occurs only when L1-ICache1 preload-operation is done.
  [0] L1_ICACHE0_PLD_DONE_INT_ST — The bit indicates the status of the interrupt that occurs only when L1-ICache0 preload-operation is done.
